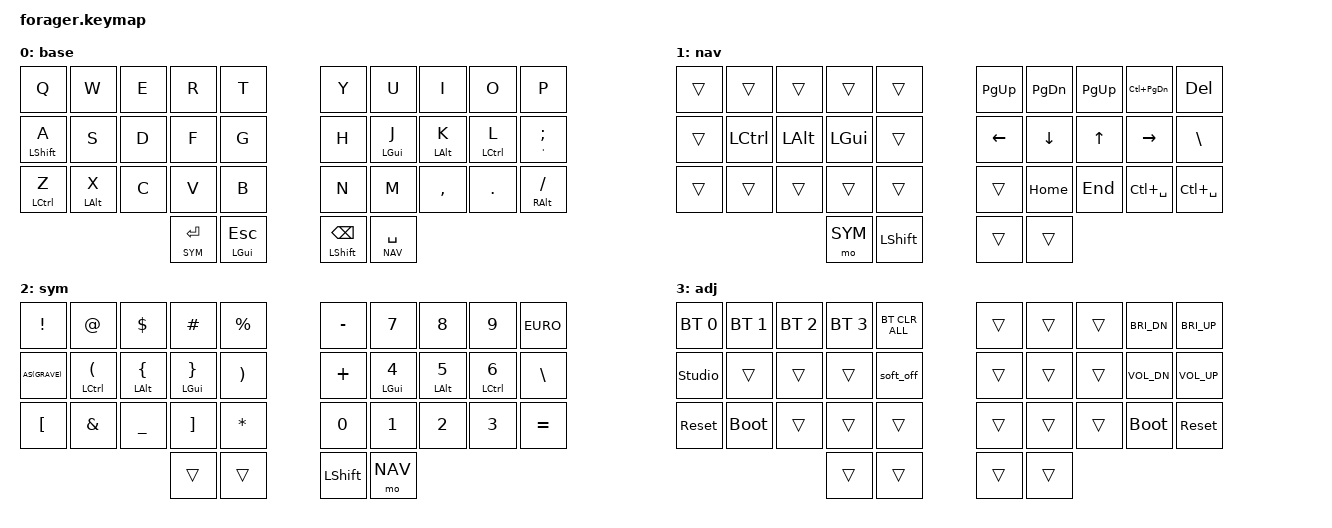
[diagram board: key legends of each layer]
#include <behaviors.dtsi>
#include <dt-bindings/zmk/keys.h>
#include <dt-bindings/zmk/bt.h>
#include <dt-bindings/zmk/outputs.h>

#define BASE 0
#define NAV  1
#define SYM  2
#define ADJ  3

#define AS(keycode) &as LS(keycode) keycode     // Autoshift Macro
#define MEH LS(LC(LALT))
#define EURO LA(LS(N2))

/ {
    behaviors {
        as: auto_shift {
            compatible = "zmk,behavior-hold-tap";
            #binding-cells = <2>;
            tapping-term-ms = <250>;
            require-prior-idle-ms = <100>;
            flavor = "tap-preferred";
            bindings = <&kp>, <&kp>;
        };
        ht: hold_tap {
            compatible = "zmk,behavior-hold-tap";
            #binding-cells = <2>;
            tapping-term-ms = <200>;
            flavor = "balanced";
            bindings = <&kp>, <&kp>;
        };
        sabk: shift_to_alt_backspace {
            compatible = "zmk,behavior-mod-morph";
            #binding-cells = <0>;
            bindings = <&kp BSPC>, <&kp LA(BSPC)>;
            mods = <(MOD_LSFT|MOD_RSFT)>;
        };
        smart_shift: smart_shift {
            compatible = "zmk,behavior-mod-morph";
            #binding-cells = <0>;
            bindings = <&sk LSHFT>, <&caps_word>;
            mods = <(MOD_LSFT|MOD_RSFT)>;
        };
        sym_bspc: left_thumb_hold_tap {
            compatible = "zmk,behavior-hold-tap";
            #binding-cells = <2>;
            flavor = "tap-preferred";
            tapping-term-ms = <150>;
            quick-tap-ms = <200>;
            bindings = <&mo>, <&sabk>;
        };
        lhm: left_homerow_mods {
            compatible = "zmk,behavior-hold-tap";
            #binding-cells = <2>;
            flavor = "balanced";
            tapping-term-ms = <280>;
            quick-tap-ms = <175>;
            require-prior-idle-ms = <150>;
            bindings = <&kp>, <&kp>;
            hold-trigger-key-positions = <5 6 7 8 9 15 16 17 18 19 25 26 27 28 29 30 31 32 33>;
        };
        rhm: right_homerow_mods {
            compatible = "zmk,behavior-hold-tap";
            #binding-cells = <2>;
            flavor = "balanced";
            tapping-term-ms = <280>;
            quick-tap-ms = <175>;
            require-prior-idle-ms = <150>;
            bindings = <&kp>, <&kp>;
            hold-trigger-key-positions = <0 1 2 3 4 10 11 12 13 14 20 21 22 23 24 30 31 32 33>;
        };
    };

    conditional_layers {
        compatible = "zmk,conditional-layers";
        tri_layer {
            if-layers = <1 2>;
            then-layer = <3>;
        };
    };

    keymap {
        compatible = "zmk,keymap";

        base {
            bindings = <
            &kp Q           &kp W           &kp E           &kp R           &kp T                                           &kp Y           &kp U           &kp I           &kp O           &kp P
            &mt LSHFT A     &kp S           &kp D           &kp F           &kp G                                           &kp H           &mt LGUI J      &mt LALT K      &mt LCTRL L     &as APOS SEMI
            &mt LCTRL Z     &mt LALT X      &kp C           &kp V           &kp B                                           &kp N           &kp M           &kp COMMA       &kp DOT         &mt RALT FSLH
                                                                            &lt SYM RET     &mt LGUI ESC    &mt LSHFT BSPC  &lt NAV SPACE
            >;
        };

        nav {
            bindings = <
            &trans          &trans          &trans          &trans          &trans                                          &kp PAGE_UP     &kp PAGE_DOWN   &kp PAGE_UP     &kp LC(PG_DN)   &kp DELETE
            &trans          &kp LCTRL       &kp LALT        &kp LGUI        &trans                                          &kp LEFT        &kp DOWN        &kp UP          &kp RIGHT       &kp BSLH
            &trans          &trans          &trans          &trans          &trans                                          &trans          &kp HOME        &kp END         &kp LC(SPACE)   &kp LC(SPACE)
                                                                            &mo SYM         &kp LSHFT       &trans          &trans
            >;
        };

        sym {
            bindings = <
            &kp EXCL        &kp AT          &kp DLLR        &kp HASH        &kp PERCENT                                     &kp MINUS       &kp N7          &kp N8          &kp N9          &kp EURO
            AS(GRAVE)       &mt LCTRL LPAR  &mt LALT LBRC   &mt LGUI RBRC   &kp RPAR                                        &kp PLUS        &mt LGUI N4     &mt LALT N5     &mt LCTRL N6    &kp BSLH
            &kp LBKT        &kp AMPS        &kp UNDER       &kp RBKT        &kp ASTERISK                                    &kp N0          &kp N1          &kp N2          &kp N3          &kp EQUAL
                                                                            &trans          &trans          &kp LSHFT       &mo NAV
            >;
        };

        adj {
            bindings = <
            &bt BT_SEL 0    &bt BT_SEL 1    &bt BT_SEL 2    &bt BT_SEL 3    &bt BT_CLR_ALL                                  &trans          &trans          &trans          &kp C_BRI_DN    &kp C_BRI_UP
            &studio_unlock  &trans          &trans          &trans          &soft_off                                       &trans          &trans          &trans          &kp C_VOL_DN    &kp C_VOL_UP
            &sys_reset      &bootloader     &trans          &trans          &trans                                          &trans          &trans          &trans          &bootloader     &sys_reset
                                                                            &trans          &trans          &trans          &trans
            >;
        };
    };
};

&lt {
    // require-prior-idle-ms = <100>;
    tapping-term-ms = <150>;
    quick-tap-ms = <200>;
};

&mt {
    tapping-term-ms = <280>;
    quick-tap-ms = <175>;
    require-prior-idle-ms = <150>;
};

&sk {
    release-after-ms = <500>;
    quick-release;
};
